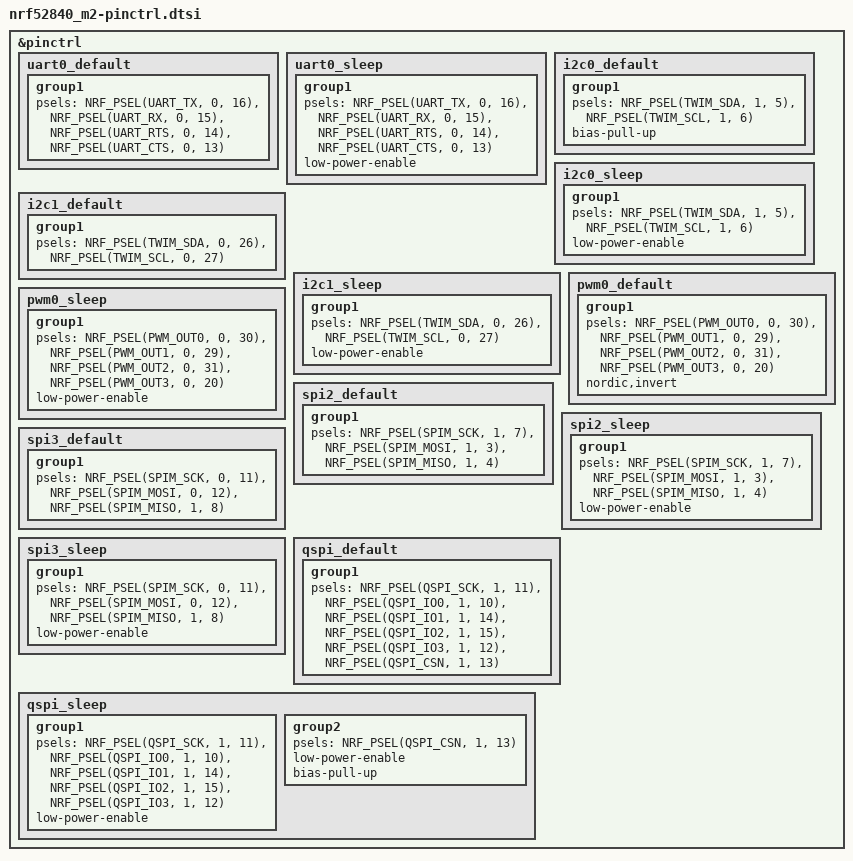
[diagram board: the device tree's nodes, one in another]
/*
 * Copyright (c) 2024 Stavros Avramidis <stavros9899@gmail.com>
 * Copyright (c) 2022 Nordic Semiconductor
 *
 * SPDX-License-Identifier: Apache-2.0
 */

 &pinctrl {
    uart0_default: uart0_default {
        group1 {
            psels = <NRF_PSEL(UART_TX, 0, 16)>,
                    <NRF_PSEL(UART_RX, 0, 15)>,
                    <NRF_PSEL(UART_RTS, 0, 14)>,
                    <NRF_PSEL(UART_CTS, 0, 13)>;
        };
    };

    uart0_sleep: uart0_sleep {
        group1 {
            psels = <NRF_PSEL(UART_TX, 0, 16)>,
                    <NRF_PSEL(UART_RX, 0, 15)>,
                    <NRF_PSEL(UART_RTS, 0, 14)>,
                    <NRF_PSEL(UART_CTS, 0, 13)>;
            low-power-enable;
        };
    };

    i2c0_default: i2c0_default {
        group1 {
            psels = <NRF_PSEL(TWIM_SDA, 1, 5)>,
                    <NRF_PSEL(TWIM_SCL, 1, 6)>;
            bias-pull-up;
        };
    };

    i2c0_sleep: i2c0_sleep {
        group1 {
            psels = <NRF_PSEL(TWIM_SDA, 1, 5)>,
                    <NRF_PSEL(TWIM_SCL, 1, 6)>;
            low-power-enable;
        };
    };

    i2c1_default: i2c1_default {
        group1 {
            psels = <NRF_PSEL(TWIM_SDA, 0, 26)>,
                    <NRF_PSEL(TWIM_SCL, 0, 27)>;
        };
    };

    i2c1_sleep: i2c1_sleep {
        group1 {
            psels = <NRF_PSEL(TWIM_SDA, 0, 26)>,
                    <NRF_PSEL(TWIM_SCL, 0, 27)>;
            low-power-enable;
        };
    };

    pwm0_default: pwm0_default {
        group1 {
            psels = <NRF_PSEL(PWM_OUT0, 0, 30)>,
                    <NRF_PSEL(PWM_OUT1, 0, 29)>,
                    <NRF_PSEL(PWM_OUT2, 0, 31)>,
                    <NRF_PSEL(PWM_OUT3, 0, 20)>;
            nordic,invert;
        };
    };

    pwm0_sleep: pwm0_sleep {
        group1 {
            psels = <NRF_PSEL(PWM_OUT0, 0, 30)>,
                    <NRF_PSEL(PWM_OUT1, 0, 29)>,
                    <NRF_PSEL(PWM_OUT2, 0, 31)>,
                    <NRF_PSEL(PWM_OUT3, 0, 20)>;
            low-power-enable;
        };
    };

    spi2_default: spi2_default {
        group1 {
            psels = <NRF_PSEL(SPIM_SCK, 1, 7)>,
                    <NRF_PSEL(SPIM_MOSI, 1, 3)>,
                    <NRF_PSEL(SPIM_MISO, 1, 4)>;
        };
    };

    spi2_sleep: spi2_sleep {
        group1 {
            psels = <NRF_PSEL(SPIM_SCK, 1, 7)>,
                    <NRF_PSEL(SPIM_MOSI, 1, 3)>,
                    <NRF_PSEL(SPIM_MISO, 1, 4)>;
            low-power-enable;
        };
    };

    spi3_default: spi3_default {
        group1 {
            psels = <NRF_PSEL(SPIM_SCK, 0, 11)>,
                    <NRF_PSEL(SPIM_MOSI, 0, 12)>,
                    <NRF_PSEL(SPIM_MISO, 1, 8)>;
        };
    };

    spi3_sleep: spi3_sleep {
        group1 {
            psels = <NRF_PSEL(SPIM_SCK, 0, 11)>,
                    <NRF_PSEL(SPIM_MOSI, 0, 12)>,
                    <NRF_PSEL(SPIM_MISO, 1, 8)>;
            low-power-enable;
        };
    };

    qspi_default: qspi_default {
        group1 {
            psels = <NRF_PSEL(QSPI_SCK, 1, 11)>,
                    <NRF_PSEL(QSPI_IO0, 1, 10)>,
                    <NRF_PSEL(QSPI_IO1, 1, 14)>,
                    <NRF_PSEL(QSPI_IO2, 1, 15)>,
                    <NRF_PSEL(QSPI_IO3, 1, 12)>,
                    <NRF_PSEL(QSPI_CSN, 1, 13)>;
        };
    };

    qspi_sleep: qspi_sleep {
        group1 {
            psels = <NRF_PSEL(QSPI_SCK, 1, 11)>,
                    <NRF_PSEL(QSPI_IO0, 1, 10)>,
                    <NRF_PSEL(QSPI_IO1, 1, 14)>,
                    <NRF_PSEL(QSPI_IO2, 1, 15)>,
                    <NRF_PSEL(QSPI_IO3, 1, 12)>;
            low-power-enable;
        };
        group2 {
            psels = <NRF_PSEL(QSPI_CSN, 1, 13)>;
            low-power-enable;
            bias-pull-up;
        };
    };

};
